# SMS0_PWRCTRL_0_PWR register map
Vendor: Texas Instruments
Peripheral module from a debugger description file (folder am62P).
Registers are 32-bit, read-write, reset 0x0 unless marked. A register's access mark holds for its fields unless they carry their own. Offsets are as the file gives them; lines under a group give offsets from that group; [hi:lo] are bit positions; {n}, {i} and the like mark numbered series; 'fields as' and 'values as' point back to an identical list; <NAME> marks a mode.

## SMS0_PWRCTRL_0_PWR
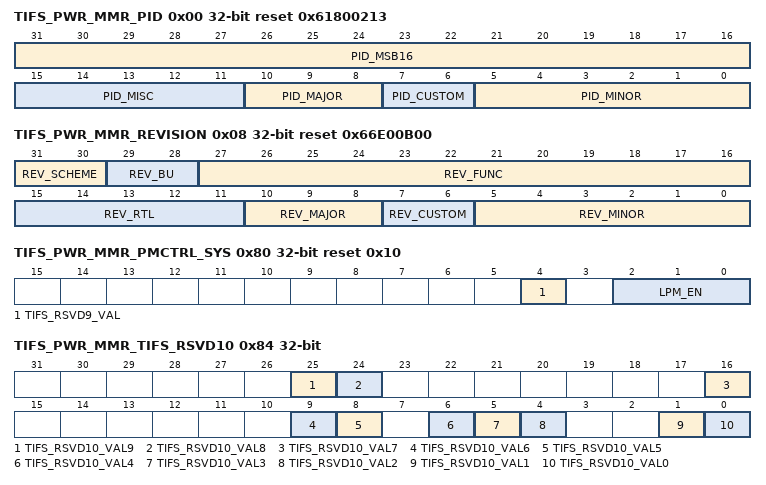
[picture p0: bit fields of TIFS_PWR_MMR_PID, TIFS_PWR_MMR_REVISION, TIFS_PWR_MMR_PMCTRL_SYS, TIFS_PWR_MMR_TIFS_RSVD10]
0x00 TIFS_PWR_MMR_PID ro reset 0x61800213
  [31:16] PID_MSB16, [15:11] PID_MISC, [10:8] PID_MAJOR, [7:6] PID_CUSTOM, [5:0] PID_MINOR
0x08 TIFS_PWR_MMR_REVISION ro reset 0x66E00B00
  [31:30] REV_SCHEME — RTL version
  [29:28] REV_BU — RTL version
  [27:16] REV_FUNC — RTL version
  [15:11] REV_RTL — RTL version
  [10:8] REV_MAJOR — Major revision
  [7:6] REV_CUSTOM — Non custom (standard) revision
  [5:0] REV_MINOR — Minor revision
0x20 TIFS_PWR_MMR_LOCK0_KICK0
  [31:0] LOCK0_KICK0 — - KICK0 component
0x24 TIFS_PWR_MMR_LOCK0_KICK1
  [31:0] LOCK0_KICK1 — - KICK1 component
0x40 TIFS_PWR_MMR_TIFS_RSVD1 ro
  [31:0] TIFS_RSVD1_VAL
0x44 TIFS_PWR_MMR_TIFS_RSVD2 access not given
  [31:0] TIFS_RSVD2_VAL — (access R/W1TS)
0x48 TIFS_PWR_MMR_TIFS_RSVD3 access not given
  [31:0] TIFS_RSVD3_VAL — (access R/W1TC)
0x4C TIFS_PWR_MMR_TIFS_RSVD4 ro
  [31:0] TIFS_RSVD4_VAL
0x50 TIFS_PWR_MMR_TIFS_RSVD5 ro
  [31:0] TIFS_RSVD5_VAL
0x54 TIFS_PWR_MMR_TIFS_RSVD6 access not given
  [31:0] TIFS_RSVD6_VAL — (access R/W1TS)
0x58 TIFS_PWR_MMR_TIFS_RSVD7 access not given
  [31:0] TIFS_RSVD7_VAL — (access R/W1TC)
0x5C TIFS_PWR_MMR_TIFS_RSVD8 ro
  [31:0] TIFS_RSVD8_VAL
0x80 TIFS_PWR_MMR_PMCTRL_SYS reset 0x10
  [4] TIFS_RSVD9_VAL, [2:0] LPM_EN
0x84 TIFS_PWR_MMR_TIFS_RSVD10 access per field
  [25] TIFS_RSVD10_VAL9 ro, [24] TIFS_RSVD10_VAL8 rw, [16] TIFS_RSVD10_VAL7 rw, [9] TIFS_RSVD10_VAL6 ro, [8] TIFS_RSVD10_VAL5 rw, [6] TIFS_RSVD10_VAL4 rw, [5] TIFS_RSVD10_VAL3 ro, [4] TIFS_RSVD10_VAL2 rw, [1] TIFS_RSVD10_VAL1 ro, [0] TIFS_RSVD10_VAL0 rw
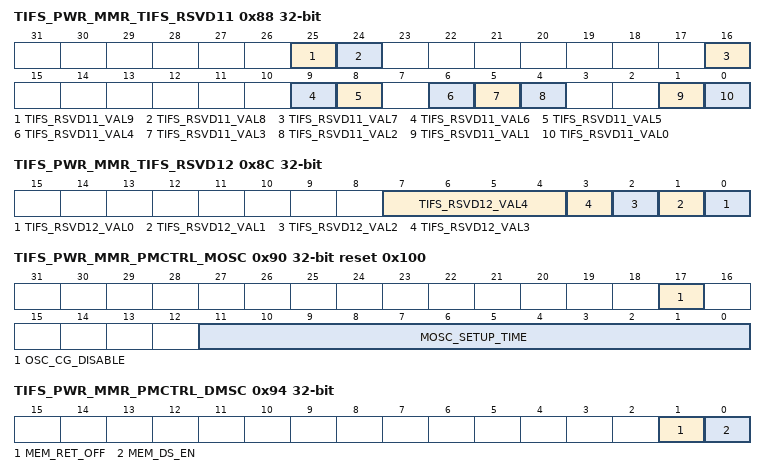
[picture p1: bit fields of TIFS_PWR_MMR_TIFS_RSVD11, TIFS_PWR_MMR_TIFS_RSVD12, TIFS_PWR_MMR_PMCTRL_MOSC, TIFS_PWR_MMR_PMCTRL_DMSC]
0x88 TIFS_PWR_MMR_TIFS_RSVD11 access per field
  [25] TIFS_RSVD11_VAL9 ro, [24] TIFS_RSVD11_VAL8 rw, [16] TIFS_RSVD11_VAL7 rw, [9] TIFS_RSVD11_VAL6 ro, [8] TIFS_RSVD11_VAL5 rw, [6] TIFS_RSVD11_VAL4 rw, [5] TIFS_RSVD11_VAL3 ro, [4] TIFS_RSVD11_VAL2 rw, [1] TIFS_RSVD11_VAL1 ro, [0] TIFS_RSVD11_VAL0 rw
0x8C TIFS_PWR_MMR_TIFS_RSVD12
  [7:4] TIFS_RSVD12_VAL4, [n] TIFS_RSVD12_VAL{n} (n=0..3)
0x90 TIFS_PWR_MMR_PMCTRL_MOSC reset 0x100
  [17] OSC_CG_DISABLE, [11:0] MOSC_SETUP_TIME
0x94 TIFS_PWR_MMR_PMCTRL_DMSC
  [1] MEM_RET_OFF, [0] MEM_DS_EN
0x98 TIFS_PWR_MMR_PM_MISC_STATUS ro
  [1:0] OSC_CG_STAT
0x140 TIFS_PWR_MMR_CPU_STCALIB reset 0xEA60
  [23:0] CPU_STCALIB_TENMS
0x180 TIFS_PWR_MMR_TIFS_RSVD13
  [31:0] TIFS_RSVD13_VAL0
0x184 TIFS_PWR_MMR_TIFS_RSVD14
  [31:0] TIFS_RSVD14_VAL0
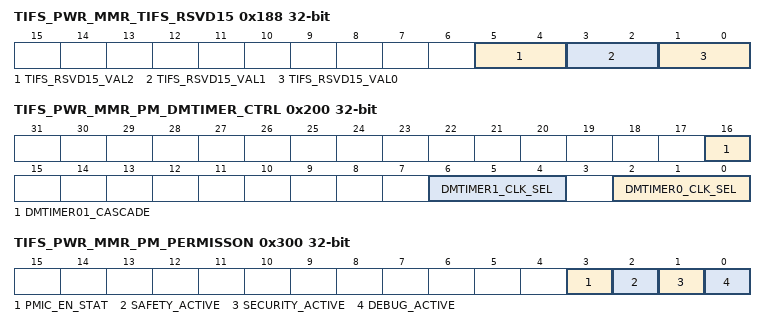
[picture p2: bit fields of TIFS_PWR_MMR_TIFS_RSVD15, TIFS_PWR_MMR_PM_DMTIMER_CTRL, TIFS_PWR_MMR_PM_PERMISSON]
0x188 TIFS_PWR_MMR_TIFS_RSVD15
  [5:4] TIFS_RSVD15_VAL2, [3:2] TIFS_RSVD15_VAL1, [1:0] TIFS_RSVD15_VAL0
0x200 TIFS_PWR_MMR_PM_DMTIMER_CTRL
  [16] DMTIMER01_CASCADE, [6:4] DMTIMER1_CLK_SEL, [2:0] DMTIMER0_CLK_SEL
0x300 TIFS_PWR_MMR_PM_PERMISSON ro
  [3] PMIC_EN_STAT, [2] SAFETY_ACTIVE, [1] SECURITY_ACTIVE, [0] DEBUG_ACTIVE
